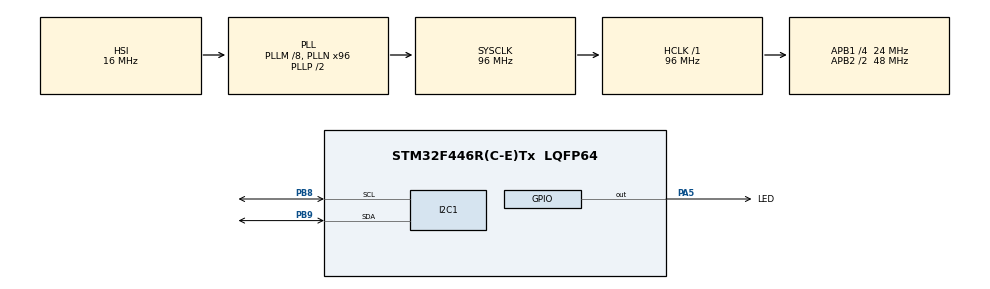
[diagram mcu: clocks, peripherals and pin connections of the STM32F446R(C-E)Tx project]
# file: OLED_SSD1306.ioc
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I2C1.I2C_Mode=I2C_Fast
Mcu.Family=STM32F4
Mcu.Name=STM32F446R(C-E)Tx
Mcu.Package=LQFP64
NVIC.PriorityGroup=NVIC_PRIORITYGROUP_4
PA13.Mode=Serial_Wire
PA13.Signal=SYS_JTMS-SWDIO
PA14.Mode=Serial_Wire
PA14.Signal=SYS_JTCK-SWCLK
PA5.GPIO_Label=LED
PA5.Signal=GPIO_Output
PB8.Mode=I2C
PB8.Signal=I2C1_SCL
PB9.Mode=I2C
PB9.Signal=I2C1_SDA
ProjectManager.HeapSize=0x200
ProjectManager.StackSize=0x400
ProjectManager.TargetToolchain=STM32CubeIDE
RCC.AHBFreq_Value=96000000
RCC.APB1CLKDivider=RCC_HCLK_DIV4
RCC.APB1Freq_Value=24000000
RCC.APB1TimFreq_Value=48000000
RCC.APB2CLKDivider=RCC_HCLK_DIV2
RCC.APB2Freq_Value=48000000
RCC.APB2TimFreq_Value=96000000
RCC.CortexFreq_Value=96000000
RCC.HCLKFreq_Value=96000000
RCC.PLLM=8
RCC.PLLN=96
RCC.SYSCLKFreq_VALUE=96000000
RCC.SYSCLKSource=RCC_SYSCLKSOURCE_PLLCLK
RCC.USBFreq_Value=96000000
RCC.VCOOutputFreq_Value=192000000
board=custom

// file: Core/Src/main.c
/* USER CODE BEGIN Header */
/**
  ******************************************************************************
  * @file           : main.c
  * @brief          : Main program body
  ******************************************************************************
  * @attention
  *
  * Copyright (c) 2022 STMicroelectronics.
  * All rights reserved.
  *
  * This software is licensed under terms that can be found in the LICENSE file
  * in the root directory of this software component.
  * If no LICENSE file comes with this software, it is provided AS-IS.
  *
  ******************************************************************************
  */
/* USER CODE END Header */
#include "main.h"

/* USER CODE BEGIN Includes */
#include "stdio.h"
#include "OLED_SSD1306.h"
#include "IMAGENES.h"
/* USER CODE END Includes */

I2C_HandleTypeDef hi2c1;

/* USER CODE BEGIN PV */
char buff[16];
/* USER CODE END PV */

void SystemClock_Config(void);
static void MX_GPIO_Init(void);
static void MX_I2C1_Init(void);

int main(void)
{

  /* MCU Configuration--------------------------------------------------------*/

  /* Reset of all peripherals, Initializes the Flash interface and the Systick. */
  HAL_Init();

  /* Configure the system clock */
  SystemClock_Config();

  /* Initialize all configured peripherals */
  MX_GPIO_Init();
  MX_I2C1_Init();
  /* USER CODE BEGIN 2 */
  OLED_Init();

  /* USER CODE END 2 */

  /* Infinite loop */
  /* USER CODE BEGIN WHILE */

  while (1)
  {
      OLED_Print_Text(0,0,1," ANGLAS MECHATRONICS ");
      OLED_Print_Text(1,0,1,"LIBRERIA DISPLAY OLED");
      OLED_Print_Text(2,0,2," OLED SSD1306 ");
      OLED_Print_Text(4,0,1,"0123456789-!#$%&/()=?");
      OLED_Print_Text(5,0,3,"ANGLAS");
      HAL_Delay(4000);
      OLED_Clear();

	  OLED_Print_Text(0,12,1,"Velocidad = ");
	  OLED_Print_Text(2,0,2,"Volumen = ");
      OLED_Print_Text(5,16,3,"I=");

      float velocidad=35.7;
      float volumen=2.6;
      uint8_t corriente=19;

		for(uint8_t i=0; i<40;i++){
          sprintf(buff,"%2.1fm/s",velocidad);
          OLED_Print_Text(0,72,1,buff);
          velocidad=velocidad+0.1;

          sprintf(buff,"%2.1fml",volumen);
          OLED_Print_Text(2,83,2,buff);
          volumen=volumen+0.1;

          sprintf(buff,"%2dA",corriente);
          OLED_Print_Text(5,56,3,buff);
          corriente++;
          HAL_Delay(100);
      }
		OLED_Clear();

		OLED_Print_Text(0,0,1, "PAGINA 01");
		OLED_Print_Text(1,1,1, "PAGINA 02");
		OLED_Print_Text(2,2,1, "PAGINA 03");
		OLED_Print_Text(3,3,1, "PAGINA 04");
		OLED_Print_Text(4,4,1, "PAGINA 05");
		OLED_Print_Text(5,5,1, "PAGINA 06");
		OLED_Print_Text(6,6,1, "PAGINA 07");
		OLED_Print_Text(7,7,1, "PAGINA 08");
		HAL_Delay(500);
		OLED_Print_Text(0,74,1, "PAGINA 01");
		OLED_Print_Text(1,73,1, "PAGINA 02");
		OLED_Print_Text(2,72,1, "PAGINA 03");
		OLED_Print_Text(3,71,1, "PAGINA 04");
		OLED_Print_Text(4,70,1, "PAGINA 05");
		OLED_Print_Text(5,69,1, "PAGINA 06");
		OLED_Print_Text(6,68,1, "PAGINA 07");
		OLED_Print_Text(7,67,1, "PAGINA 08");
		HAL_Delay(4000);

		OLED_Imagen(house);
		HAL_Delay(500);
		OLED_Imagen(mikro_logo);
		HAL_Delay(500);
		OLED_Imagen(blink1);
		HAL_Delay(500);
		OLED_Imagen(blink2);
		HAL_Delay(500);
		OLED_Clear();
    /* USER CODE END WHILE */

  }
}

void SystemClock_Config(void)
{
  RCC_OscInitTypeDef RCC_OscInitStruct = {0};
  RCC_ClkInitTypeDef RCC_ClkInitStruct = {0};

  /** Configure the main internal regulator output voltage
  */
  __HAL_RCC_PWR_CLK_ENABLE();
  __HAL_PWR_VOLTAGESCALING_CONFIG(PWR_REGULATOR_VOLTAGE_SCALE3);

  /** Initializes the RCC Oscillators according to the specified parameters
  * in the RCC_OscInitTypeDef structure.
  */
  RCC_OscInitStruct.OscillatorType = RCC_OSCILLATORTYPE_HSI;
  RCC_OscInitStruct.HSIState = RCC_HSI_ON;
  RCC_OscInitStruct.HSICalibrationValue = RCC_HSICALIBRATION_DEFAULT;
  RCC_OscInitStruct.PLL.PLLState = RCC_PLL_ON;
  RCC_OscInitStruct.PLL.PLLSource = RCC_PLLSOURCE_HSI;
  RCC_OscInitStruct.PLL.PLLM = 8;
  RCC_OscInitStruct.PLL.PLLN = 96;
  RCC_OscInitStruct.PLL.PLLP = RCC_PLLP_DIV2;
  RCC_OscInitStruct.PLL.PLLQ = 2;
  RCC_OscInitStruct.PLL.PLLR = 2;
  if (HAL_RCC_OscConfig(&RCC_OscInitStruct) != HAL_OK)
  {
    Error_Handler();
  }

  /** Initializes the CPU, AHB and APB buses clocks
  */
  RCC_ClkInitStruct.ClockType = RCC_CLOCKTYPE_HCLK|RCC_CLOCKTYPE_SYSCLK
                              |RCC_CLOCKTYPE_PCLK1|RCC_CLOCKTYPE_PCLK2;
  RCC_ClkInitStruct.SYSCLKSource = RCC_SYSCLKSOURCE_PLLCLK;
  RCC_ClkInitStruct.AHBCLKDivider = RCC_SYSCLK_DIV1;
  RCC_ClkInitStruct.APB1CLKDivider = RCC_HCLK_DIV4;
  RCC_ClkInitStruct.APB2CLKDivider = RCC_HCLK_DIV2;

  if (HAL_RCC_ClockConfig(&RCC_ClkInitStruct, FLASH_LATENCY_3) != HAL_OK)
  {
    Error_Handler();
  }
}

static void MX_I2C1_Init(void)
{

  hi2c1.Instance = I2C1;
  hi2c1.Init.ClockSpeed = 400000;
  hi2c1.Init.DutyCycle = I2C_DUTYCYCLE_2;
  hi2c1.Init.OwnAddress1 = 0;
  hi2c1.Init.AddressingMode = I2C_ADDRESSINGMODE_7BIT;
  hi2c1.Init.DualAddressMode = I2C_DUALADDRESS_DISABLE;
  hi2c1.Init.OwnAddress2 = 0;
  hi2c1.Init.GeneralCallMode = I2C_GENERALCALL_DISABLE;
  hi2c1.Init.NoStretchMode = I2C_NOSTRETCH_DISABLE;
  if (HAL_I2C_Init(&hi2c1) != HAL_OK)
  {
    Error_Handler();
  }

}

static void MX_GPIO_Init(void)
{
  GPIO_InitTypeDef GPIO_InitStruct = {0};

  /* GPIO Ports Clock Enable */
  __HAL_RCC_GPIOA_CLK_ENABLE();
  __HAL_RCC_GPIOB_CLK_ENABLE();

  /*Configure GPIO pin Output Level */
  HAL_GPIO_WritePin(LED_GPIO_Port, LED_Pin, GPIO_PIN_RESET);

  /*Configure GPIO pin : LED_Pin */
  GPIO_InitStruct.Pin = LED_Pin;
  GPIO_InitStruct.Mode = GPIO_MODE_OUTPUT_PP;
  GPIO_InitStruct.Pull = GPIO_NOPULL;
  GPIO_InitStruct.Speed = GPIO_SPEED_FREQ_LOW;
  HAL_GPIO_Init(LED_GPIO_Port, &GPIO_InitStruct);

}

void Error_Handler(void)
{
  __disable_irq();
  while (1)
  {
  }
}
